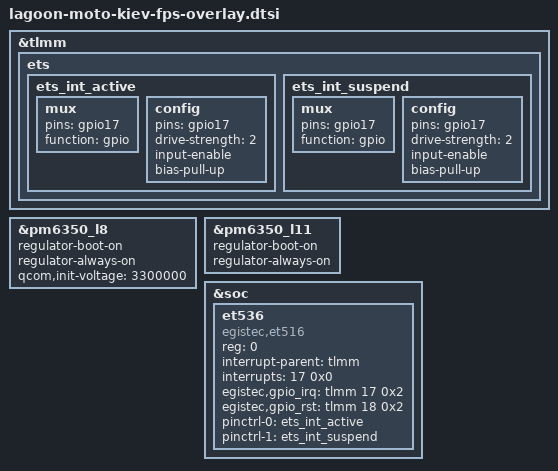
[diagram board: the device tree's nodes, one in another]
&tlmm {
	ets {
		ets_int_active: ets_int_active {
			/* INTERRUPT */
			mux {
				pins = "gpio17";
				function = "gpio";
			};

			config {
				pins = "gpio17";
				drive-strength = <2>; /* 2 MA */
				input-enable;
				bias-pull-up;
			};
		};
		ets_int_suspend: ets_int_suspend {
			/* INTERRUPT */
			mux {
				pins = "gpio17";
				function = "gpio";
			};

			config {
				pins = "gpio17";
				drive-strength = <2>; /* 2 MA */
				input-enable;
				bias-pull-up;
			};
		};
	};
};

&pm6350_l8 {
	regulator-boot-on;
	regulator-always-on;
	qcom,init-voltage = <3300000>;
	status = "ok";
};

&pm6350_l11 {
	regulator-boot-on;
	regulator-always-on;
	status = "ok";
};

&soc {
	et536 {
		compatible = "egistec,et516";
		status = "ok";
		reg = <0>;
		interrupt-parent = <&tlmm>;
		interrupts = <17 0x0>;
		egistec,gpio_irq = <&tlmm 17 0x2>;
		egistec,gpio_rst = <&tlmm 18 0x2>;
		pinctrl-names = "default", "suspend";
		pinctrl-0 = <&ets_int_active>;
		pinctrl-1 = <&ets_int_suspend>;
	};
};
